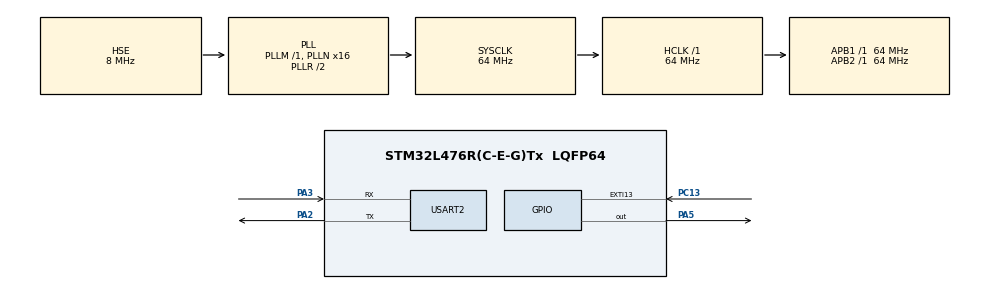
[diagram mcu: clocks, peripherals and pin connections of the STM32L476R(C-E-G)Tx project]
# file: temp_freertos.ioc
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Dma.Request0=USART2_RX
Dma.USART2_RX.0.Direction=DMA_PERIPH_TO_MEMORY
Dma.USART2_RX.0.Instance=DMA1_Channel6
Dma.USART2_RX.0.MemDataAlignment=DMA_MDATAALIGN_BYTE
Dma.USART2_RX.0.MemInc=DMA_MINC_ENABLE
Dma.USART2_RX.0.Mode=DMA_CIRCULAR
Dma.USART2_RX.0.PeriphDataAlignment=DMA_PDATAALIGN_BYTE
Dma.USART2_RX.0.PeriphInc=DMA_PINC_DISABLE
Dma.USART2_RX.0.Priority=DMA_PRIORITY_LOW
FREERTOS.HEAP_NUMBER=4
FREERTOS.Tasks01=defaultTask,24,128,StartDefaultTask,Default,NULL,Dynamic,NULL,NULL
FREERTOS.configCHECK_FOR_STACK_OVERFLOW=0
FREERTOS.configENABLE_FPU=0
FREERTOS.configGENERATE_RUN_TIME_STATS=1
FREERTOS.configRECORD_STACK_HIGH_ADDRESS=1
FREERTOS.configTOTAL_HEAP_SIZE=6000
FREERTOS.configUSE_APPLICATION_TASK_TAG=0
FREERTOS.configUSE_IDLE_HOOK=0
FREERTOS.configUSE_MALLOC_FAILED_HOOK=0
FREERTOS.configUSE_STATS_FORMATTING_FUNCTIONS=1
Mcu.Family=STM32L4
Mcu.Name=STM32L476R(C-E-G)Tx
Mcu.Package=LQFP64
NVIC.DMA1_Channel6_IRQn=true\:5\:0\:false\:false\:true\:true\:false\:true
NVIC.EXTI15_10_IRQn=true\:5\:0\:false\:false\:true\:true\:true\:true
NVIC.PriorityGroup=NVIC_PRIORITYGROUP_4
NVIC.TIM4_IRQn=true\:0\:0\:false\:false\:true\:false\:false\:true
NVIC.TimeBase=TIM4_IRQn
NVIC.TimeBaseIP=TIM4
NVIC.USART2_IRQn=true\:5\:0\:false\:false\:true\:true\:true\:true
PA13\ (JTMS-SWDIO).Mode=Serial_Wire
PA13\ (JTMS-SWDIO).Signal=SYS_JTMS-SWDIO
PA14\ (JTCK-SWCLK).Mode=Serial_Wire
PA14\ (JTCK-SWCLK).Signal=SYS_JTCK-SWCLK
PA2.Mode=Asynchronous
PA2.Signal=USART2_TX
PA3.Mode=Asynchronous
PA3.Signal=USART2_RX
PA5.GPIO_PuPd=GPIO_PULLDOWN
PA5.GPIO_Speed=GPIO_SPEED_FREQ_MEDIUM
PA5.Signal=GPIO_Output
PC13.GPIO_PuPd=GPIO_PULLUP
PC13.Signal=GPXTI13
PH0-OSC_IN\ (PH0).Mode=HSE-External-Oscillator
PH0-OSC_IN\ (PH0).Signal=RCC_OSC_IN
PH1-OSC_OUT\ (PH1).Mode=HSE-External-Oscillator
PH1-OSC_OUT\ (PH1).Signal=RCC_OSC_OUT
ProjectManager.HeapSize=0x2000
ProjectManager.StackSize=0x4000
ProjectManager.TargetToolchain=MDK-ARM V5.27
RCC.ADCFreq_Value=32000000
RCC.AHBFreq_Value=64000000
RCC.APB1Freq_Value=64000000
RCC.APB1TimFreq_Value=64000000
RCC.APB2Freq_Value=64000000
RCC.APB2TimFreq_Value=64000000
RCC.CortexFreq_Value=64000000
RCC.HCLKFreq_Value=64000000
RCC.HSE_VALUE=8000000
RCC.HSI_VALUE=16000000
RCC.LSE_VALUE=32768
RCC.MSI_VALUE=4000000
RCC.PLLN=16
RCC.PLLSourceVirtual=RCC_PLLSOURCE_HSE
RCC.SYSCLKFreq_VALUE=64000000
RCC.SYSCLKSource=RCC_SYSCLKSOURCE_PLLCLK
RCC.USBFreq_Value=32000000
RCC.VCOOutputFreq_Value=128000000
USART2.VirtualMode-Asynchronous=VM_ASYNC
VP_FATFS_VS_Generic.Mode=User_defined
VP_FREERTOS_VS_CMSIS_V2.Mode=CMSIS_V2
VP_SYS_VS_tim4.Mode=TIM4
board=custom

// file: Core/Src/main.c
/* USER CODE BEGIN Header */
/**
  ******************************************************************************
  * @file           : main.c
  * @brief          : Main program body
  ******************************************************************************
  * @attention
  *
  * <h2><center>&copy; Copyright (c) 2021 STMicroelectronics.
  * All rights reserved.</center></h2>
  *
  * This software component is licensed by ST under BSD 3-Clause license,
  * the "License"; You may not use this file except in compliance with the
  * License. You may obtain a copy of the License at:
  *                        opensource.org/licenses/BSD-3-Clause
  *
  ******************************************************************************
  */
/* USER CODE END Header */
#include "main.h"
#include "cmsis_os.h"
#include "fatfs.h"

/* USER CODE BEGIN Includes */

#include "rtos_debug.h"
//#include "EventRecorder.h"

/* USER CODE END Includes */

UART_HandleTypeDef huart2;
DMA_HandleTypeDef hdma_usart2_rx;

/* Definitions for defaultTask */
osThreadId_t defaultTaskHandle;
const osThreadAttr_t defaultTask_attributes = {
  .name = "defaultTask",
  .stack_size = 128 * 4,
  .priority = (osPriority_t) osPriorityNormal,
};

void SystemClock_Config(void);
static void MX_GPIO_Init(void);
static void MX_DMA_Init(void);
static void MX_USART2_UART_Init(void);
void StartDefaultTask(void *argument);

/* USER CODE BEGIN PFP */

extern osMessageQueueId_t que_id;
extern osSemaphoreId_t sem_tim;

/* USER CODE END PFP */

/* USER CODE BEGIN 0 */

uint32_t flags;

/* USER CODE END 0 */

int main(void)
{

  /* MCU Configuration--------------------------------------------------------*/

  /* Reset of all peripherals, Initializes the Flash interface and the Systick. */
  HAL_Init();

  /* Configure the system clock */
  SystemClock_Config();

  /* USER CODE BEGIN SysInit */

	//EventRecorderInitialize(EventRecordAll, 1);

  /* USER CODE END SysInit */

  /* Initialize all configured peripherals */
  MX_GPIO_Init();
  MX_DMA_Init();
  MX_USART2_UART_Init();
  MX_FATFS_Init();
  /* USER CODE BEGIN 2 */

  //USER_Usart2_Init();
  Task_init();

  /* USER CODE END 2 */

  /* Init scheduler */
  osKernelInitialize();

  /* Create the thread(s) */
  /* creation of defaultTask */
  defaultTaskHandle = osThreadNew(StartDefaultTask, NULL, &defaultTask_attributes);

  /* USER CODE BEGIN RTOS_THREADS */
  /* add threads, ... */

  //USER_Usart2_Init();

  /* USER CODE END RTOS_THREADS */

  /* Start scheduler */
  osKernelStart();

  /* We should never get here as control is now taken by the scheduler */
  /* Infinite loop */
  while (1)
  {

  }
}

void SystemClock_Config(void)
{
  RCC_OscInitTypeDef RCC_OscInitStruct = {0};
  RCC_ClkInitTypeDef RCC_ClkInitStruct = {0};

  /** Configure the main internal regulator output voltage
  */
  if (HAL_PWREx_ControlVoltageScaling(PWR_REGULATOR_VOLTAGE_SCALE1) != HAL_OK)
  {
    Error_Handler();
  }
  /** Initializes the RCC Oscillators according to the specified parameters
  * in the RCC_OscInitTypeDef structure.
  */
  RCC_OscInitStruct.OscillatorType = RCC_OSCILLATORTYPE_HSE;
  RCC_OscInitStruct.HSEState = RCC_HSE_ON;
  RCC_OscInitStruct.PLL.PLLState = RCC_PLL_ON;
  RCC_OscInitStruct.PLL.PLLSource = RCC_PLLSOURCE_HSE;
  RCC_OscInitStruct.PLL.PLLM = 1;
  RCC_OscInitStruct.PLL.PLLN = 16;
  RCC_OscInitStruct.PLL.PLLP = RCC_PLLP_DIV7;
  RCC_OscInitStruct.PLL.PLLQ = RCC_PLLQ_DIV2;
  RCC_OscInitStruct.PLL.PLLR = RCC_PLLR_DIV2;
  if (HAL_RCC_OscConfig(&RCC_OscInitStruct) != HAL_OK)
  {
    Error_Handler();
  }
  /** Initializes the CPU, AHB and APB buses clocks
  */
  RCC_ClkInitStruct.ClockType = RCC_CLOCKTYPE_HCLK|RCC_CLOCKTYPE_SYSCLK
                              |RCC_CLOCKTYPE_PCLK1|RCC_CLOCKTYPE_PCLK2;
  RCC_ClkInitStruct.SYSCLKSource = RCC_SYSCLKSOURCE_PLLCLK;
  RCC_ClkInitStruct.AHBCLKDivider = RCC_SYSCLK_DIV1;
  RCC_ClkInitStruct.APB1CLKDivider = RCC_HCLK_DIV1;
  RCC_ClkInitStruct.APB2CLKDivider = RCC_HCLK_DIV1;

  if (HAL_RCC_ClockConfig(&RCC_ClkInitStruct, FLASH_LATENCY_3) != HAL_OK)
  {
    Error_Handler();
  }
}

static void MX_USART2_UART_Init(void)
{

  huart2.Instance = USART2;
  huart2.Init.BaudRate = 115200;
  huart2.Init.WordLength = UART_WORDLENGTH_8B;
  huart2.Init.StopBits = UART_STOPBITS_1;
  huart2.Init.Parity = UART_PARITY_NONE;
  huart2.Init.Mode = UART_MODE_TX_RX;
  huart2.Init.HwFlowCtl = UART_HWCONTROL_NONE;
  huart2.Init.OverSampling = UART_OVERSAMPLING_16;
  huart2.Init.OneBitSampling = UART_ONE_BIT_SAMPLE_DISABLE;
  huart2.AdvancedInit.AdvFeatureInit = UART_ADVFEATURE_NO_INIT;
  if (HAL_UART_Init(&huart2) != HAL_OK)
  {
    Error_Handler();
  }

}

static void MX_DMA_Init(void)
{

  /* DMA controller clock enable */
  __HAL_RCC_DMA1_CLK_ENABLE();

  /* DMA interrupt init */
  /* DMA1_Channel6_IRQn interrupt configuration */
  HAL_NVIC_SetPriority(DMA1_Channel6_IRQn, 5, 0);
  HAL_NVIC_EnableIRQ(DMA1_Channel6_IRQn);

}

static void MX_GPIO_Init(void)
{
  GPIO_InitTypeDef GPIO_InitStruct = {0};

  /* GPIO Ports Clock Enable */
  __HAL_RCC_GPIOC_CLK_ENABLE();
  __HAL_RCC_GPIOH_CLK_ENABLE();
  __HAL_RCC_GPIOA_CLK_ENABLE();

  /*Configure GPIO pin Output Level */
  HAL_GPIO_WritePin(GPIOA, GPIO_PIN_5, GPIO_PIN_RESET);

  /*Configure GPIO pin : PC13 */
  GPIO_InitStruct.Pin = GPIO_PIN_13;
  GPIO_InitStruct.Mode = GPIO_MODE_IT_FALLING; //GPIO_MODE_IT_RISING_FALLING
  GPIO_InitStruct.Pull = GPIO_PULLUP;
  HAL_GPIO_Init(GPIOC, &GPIO_InitStruct);

  /*Configure GPIO pin : PA5 */
  GPIO_InitStruct.Pin = GPIO_PIN_5;
  GPIO_InitStruct.Mode = GPIO_MODE_OUTPUT_PP;
  GPIO_InitStruct.Pull = GPIO_PULLDOWN;
  GPIO_InitStruct.Speed = GPIO_SPEED_FREQ_MEDIUM;
  HAL_GPIO_Init(GPIOA, &GPIO_InitStruct);

  /* EXTI interrupt init*/
  HAL_NVIC_SetPriority(EXTI15_10_IRQn, 5, 0);
  HAL_NVIC_EnableIRQ(EXTI15_10_IRQn);

}

void StartDefaultTask(void *argument)
{
  /* USER CODE BEGIN 5 */
  /* Infinite loop */

  USER_Usart2_Init();

  for(;;)
  {

		osDelay(1);

  }
  /* USER CODE END 5 */
}

void HAL_TIM_PeriodElapsedCallback(TIM_HandleTypeDef *htim)
{
  if (htim->Instance == TIM4) {
    HAL_IncTick();
  }
}

void Error_Handler(void)
{
  __disable_irq();
  while (1)
  {
  }
}

/************************ (C) COPYRIGHT STMicroelectronics *****END OF FILE****/
